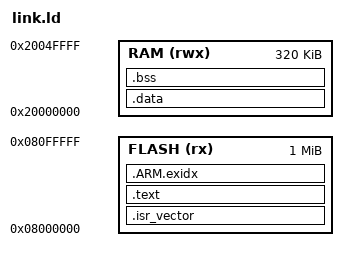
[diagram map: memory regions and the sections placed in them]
/* STM32F746ZG : flash 1 Mo @0x08000000 ; DTCM + SRAM1 + SRAM2 contiguës, 320 Ko @0x20000000 */
MEMORY
{
  FLASH (rx)  : ORIGIN = 0x08000000, LENGTH = 1M
  RAM   (rwx) : ORIGIN = 0x20000000, LENGTH = 320K
}
ENTRY(Reset_Handler)
_estack = ORIGIN(RAM) + LENGTH(RAM);
SECTIONS
{
  .isr_vector : { KEEP(*(.isr_vector)) } > FLASH
  .text : { *(.text*) *(.rodata*) . = ALIGN(4); } > FLASH
  .ARM.exidx : { *(.ARM.exidx* .gnu.linkonce.armexidx.*) } > FLASH
  _etext = ALIGN(4);
  .data : AT(_etext) { _sdata = .; *(.data*) . = ALIGN(4); _edata = .; } > RAM
  .bss  : { _sbss = .; *(.bss*) *(COMMON) . = ALIGN(4); _ebss = .; } > RAM
}
